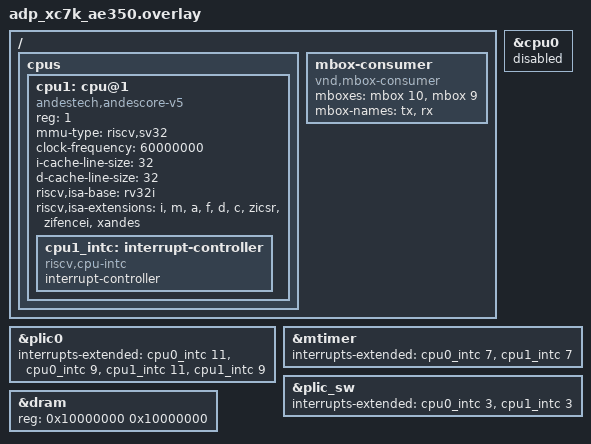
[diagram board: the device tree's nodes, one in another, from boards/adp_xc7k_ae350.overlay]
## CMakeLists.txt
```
#
# Copyright (c) 2021 Carlo Caione <ccaione@baylibre.com>
# Copyright 2023-2026 NXP
# Copyright 2025 Ezurio LLC
#
# SPDX-License-Identifier: Apache-2.0
#

cmake_minimum_required(VERSION 3.28.0)

find_package(Zephyr REQUIRED HINTS $ENV{ZEPHYR_BASE})

if(CONFIG_BOARD_ADP_XC7K_AE350_A25 OR
   CONFIG_BOARD_BL54L15_DVK_NRF54L15_CPUFLPR OR
   CONFIG_BOARD_EK_RA8P1_R7KA8P1KFLCAC_CM33 OR
   CONFIG_BOARD_ESP32C6_DEVKITC_ESP32C6_LPCORE OR
   CONFIG_BOARD_ESP32P4X_FUNCTION_EV_BOARD_ESP32P4_LPCORE OR
   CONFIG_BOARD_ESP32S3_DEVKITC_ESP32S3_APPCPU OR
   CONFIG_BOARD_ESP32_DEVKITC_ESP32_APPCPU OR
   CONFIG_BOARD_FRDM_IMXRT1186_MIMXRT1186_CM7 OR
   CONFIG_BOARD_FRDM_IMXRT700_MIMXRT798S_CM33_CPU1 OR
   CONFIG_BOARD_FRDM_MCXN947_MCXN947_CPU1 OR
   CONFIG_BOARD_IMX943_EVK_MIMX94398_M33 OR
   CONFIG_BOARD_IMX943_EVK_MIMX94398_M7_0 OR
   CONFIG_BOARD_IMX943_EVK_MIMX94398_M7_1 OR
   CONFIG_BOARD_LPCXPRESSO55S69_LPC55S69_CPU1 OR
   CONFIG_BOARD_MCX_N9XX_EVK_MCXN947_CPU1 OR
   CONFIG_BOARD_MIMXRT1160_EVK_MIMXRT1166_CM4 OR
   CONFIG_BOARD_MIMXRT1170_EVK_MIMXRT1176_CM4 OR
   CONFIG_BOARD_MIMXRT1180_EVK_MIMXRT1189_CM7 OR
   CONFIG_BOARD_MIMXRT700_EVK_MIMXRT798S_CM33_CPU1 OR
   CONFIG_BOARD_NRF5340BSIM_NRF5340_CPUNET OR
   CONFIG_BOARD_NRF5340DK_NRF5340_CPUNET OR
   CONFIG_BOARD_NRF54H20DK_NRF54H20_CPUFLPR OR
   CONFIG_BOARD_NRF54H20DK_NRF54H20_CPUPPR OR
   CONFIG_BOARD_NRF54H20DK_NRF54H20_CPURAD OR
   CONFIG_BOARD_NRF54L15DK_NRF54L15_CPUFLPR OR
   CONFIG_BOARD_NRF54LM20DK_NRF54LM20A_CPUFLPR OR
   CONFIG_BOARD_NRF54LM20DK_NRF54LM20B_CPUFLPR OR
   CONFIG_BOARD_NRF54LV10DK_NRF54LV10A_CPUFLPR OR
   CONFIG_BOARD_NRF7120DK_NRF7120_CPUFLPR OR
   CONFIG_BOARD_NRF7120DK_NRF7120E_CPUFLPR OR
   CONFIG_BOARD_NUCLEO_H755ZI_Q_STM32H755XX_M4 OR
   CONFIG_BOARD_STM32H747I_DISCO_STM32H747XX_M4 OR
   CONFIG_SOC_AMD_VERSAL2_RPU OR
   CONFIG_SOC_AMD_VERSALNET_RPU)
  message(STATUS "${BOARD}/${BOARD_QUALIFIERS} compile as remote in this sample")
else()
  message(FATAL_ERROR "${BOARD}/${BOARD_QUALIFIERS} is not supported for this sample")
endif()

project(mbox_ipc_remote)

target_sources(app PRIVATE src/main.c)
```

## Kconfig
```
# Copyright 2024 Nordic Semiconductor ASA
# SPDX-License-Identifier: Apache-2.0

source "Kconfig.zephyr"

config TX_ENABLED
	bool "TX enabled"
	default y
	help
	  Enable TX

config RX_ENABLED
	bool "RX enabled"
	default y
	help
	  Enable RX
```

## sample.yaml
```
sample:
  name: MBOX IPC sample (remote)
tests:
  sample.drivers.mbox_remote:
    platform_allow: nrf5340dk_nrf5340_cpunet adp_xc7k_ae350
    integration_platforms:
      - nrf5340dk_nrf5340_cpunet
    tags: mbox
    harness: remote
```

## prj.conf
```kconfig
CONFIG_STDOUT_CONSOLE=n
CONFIG_MBOX=y
```

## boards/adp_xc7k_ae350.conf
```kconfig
CONFIG_RV_BOOT_HART=1
CONFIG_MP_MAX_NUM_CPUS=1
```

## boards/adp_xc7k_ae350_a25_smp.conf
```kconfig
CONFIG_SMP=n
CONFIG_RV_BOOT_HART=1
CONFIG_MP_MAX_NUM_CPUS=1
```

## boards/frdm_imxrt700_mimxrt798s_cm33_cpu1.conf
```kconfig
# SPDX-FileCopyrightText: Copyright 2026 NXP
# SPDX-License-Identifier: Apache-2.0

CONFIG_BUILD_OUTPUT_HEX=y
CONFIG_SECOND_CORE_MCUX=y
CONFIG_BUILD_OUTPUT_INFO_HEADER=y
CONFIG_GLIKEY_MCUX_GLIKEY=y
```

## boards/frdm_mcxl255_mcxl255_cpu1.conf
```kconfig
CONFIG_SOC_MCXL255_SECOND_CORE=y
CONFIG_BUILD_OUTPUT_HEX=y
```

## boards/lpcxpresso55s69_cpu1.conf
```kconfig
CONFIG_SECOND_CORE_MCUX=y
CONFIG_BUILD_OUTPUT_HEX=y
CONFIG_MBOX_NXP_MAILBOX=y

# For purpose of sample enable UART Console on CPU1
CONFIG_CONSOLE=y
CONFIG_UART_CONSOLE=y
CONFIG_SERIAL=y
CONFIG_UART_INTERRUPT_DRIVEN=y
CONFIG_CLOCK_CONTROL=y
```

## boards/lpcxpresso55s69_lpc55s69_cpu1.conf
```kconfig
CONFIG_SECOND_CORE_MCUX=y
CONFIG_BUILD_OUTPUT_HEX=y

# For purpose of sample enable UART Console on CPU1
CONFIG_CONSOLE=y
CONFIG_UART_CONSOLE=y
CONFIG_SERIAL=y
CONFIG_UART_INTERRUPT_DRIVEN=y
CONFIG_CLOCK_CONTROL=y
```

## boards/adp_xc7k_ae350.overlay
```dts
/*
 * Copyright (c) 2022 Andes Technology Corporation.
 * SPDX-License-Identifier: Apache-2.0
 */

/ {
	cpus {
		cpu1: cpu@1 {
			compatible = "andestech,andescore-v5", "riscv";
			reg = <1>;
			device_type = "cpu";
			mmu-type = "riscv,sv32";
			clock-frequency = <60000000>;
			i-cache-line-size = <32>;
			d-cache-line-size = <32>;
			riscv,isa-base = "rv32i";
			riscv,isa-extensions = "i", "m", "a", "f", "d", "c", "zicsr", "zifencei",
					       "xandes";
			status = "okay";

			cpu1_intc: interrupt-controller {
				compatible = "riscv,cpu-intc";
				#address-cells = <0>;
				#interrupt-cells = <1>;
				interrupt-controller;
			};
		};
	};

	mbox-consumer {
		compatible = "vnd,mbox-consumer";
		mboxes = <&mbox 10>, <&mbox 9>;
		mbox-names = "tx", "rx";
	};
};

&cpu0 {
	status = "disabled";
};

&plic0 {
	interrupts-extended = <&cpu0_intc 11 &cpu0_intc 9
			       &cpu1_intc 11 &cpu1_intc 9>;
};

&mtimer {
	interrupts-extended = <&cpu0_intc 7 &cpu1_intc 7>;
};

&plic_sw {
	interrupts-extended = <&cpu0_intc 3 &cpu1_intc 3>;
};

&dram {
	reg = <0x10000000 0x10000000>;
};
```

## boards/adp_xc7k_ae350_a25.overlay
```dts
/*
 * Copyright (c) 2022 Andes Technology Corporation.
 * SPDX-License-Identifier: Apache-2.0
 */

/ {
	cpus {
		cpu1: cpu@1 {
			compatible = "andestech,a25", "andestech,andescore-v5", "riscv";
			reg = <1>;
			device_type = "cpu";
			mmu-type = "riscv,sv32";
			clock-frequency = <60000000>;
			i-cache-line-size = <32>;
			d-cache-line-size = <32>;
			riscv,isa-base = "rv32i";
			riscv,isa-extensions = "i", "m", "a", "f", "d", "c", "zicsr", "zifencei",
					       "zba", "zbb", "zbc", "zbs", "xandes";
			status = "okay";

			cpu1_intc: interrupt-controller {
				compatible = "riscv,cpu-intc";
				#address-cells = <0>;
				#interrupt-cells = <1>;
				interrupt-controller;
			};
		};
	};

	mbox-consumer {
		compatible = "vnd,mbox-consumer";
		mboxes = <&mbox 10>, <&mbox 9>;
		mbox-names = "tx", "rx";
	};
};

&cpu0 {
	status = "disabled";
};

&plic0 {
	interrupts-extended = <&cpu0_intc 11 &cpu0_intc 9
			       &cpu1_intc 11 &cpu1_intc 9>;
};

&mtimer {
	interrupts-extended = <&cpu0_intc 7 &cpu1_intc 7>;
};

&plic_sw {
	interrupts-extended = <&cpu0_intc 3 &cpu1_intc 3>;
};

&dram {
	reg = <0x10000000 0x10000000>;
};
```

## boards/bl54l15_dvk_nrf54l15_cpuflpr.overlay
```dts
/*
 * Copyright 2024 Nordic Semiconductor ASA
 * Copyright 2025 Ezurio LLC
 * SPDX-License-Identifier: Apache-2.0
 */

/ {
	mbox-consumer {
		compatible = "vnd,mbox-consumer";
		mboxes = <&cpuflpr_vevif_rx 21>, <&cpuflpr_vevif_tx 20>;
		mbox-names = "rx", "tx";
	};
};

&cpuflpr_vevif_rx {
	status = "okay";
};

&cpuflpr_vevif_tx {
	status = "okay";
};

&uart30 {
	/delete-property/ hw-flow-control;
};
```

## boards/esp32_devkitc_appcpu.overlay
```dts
/*
 * Copyright (c) 2024 Felipe Neves.
 *
 * SPDX-License-Identifier: Apache-2.0
 */

/ {
	chosen {
		zephyr,sram = &sram1;
		zephyr,ipc_shm = &shm0;
		zephyr,ipc = &mbox0;
	};

	mbox-consumer {
		compatible = "vnd,mbox-consumer";
		mboxes = <&mbox0 0>, <&mbox0 1>;
		mbox-names = "tx", "rx";
	};
};

&mbox0 {
	status = "okay";
};
```

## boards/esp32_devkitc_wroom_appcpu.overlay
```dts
/*
 * Copyright (c) 2024 Felipe Neves.
 *
 * SPDX-License-Identifier: Apache-2.0
 */

/ {
	chosen {
		zephyr,sram = &sram0;
		zephyr,ipc_shm = &shm0;
		zephyr,ipc = &mbox0;
	};

	mbox-consumer {
		compatible = "vnd,mbox-consumer";
		mboxes = <&mbox0 0>, <&mbox0 1>;
		mbox-names = "tx", "rx";
	};
};

&mbox0 {
	status = "okay";
};
```

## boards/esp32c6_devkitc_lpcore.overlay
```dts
/*
 * Copyright (c) 2024 Felipe Neves.
 *
 * SPDX-License-Identifier: Apache-2.0
 */

/ {
	chosen {
		zephyr,ipc_shm = &ipc_shm;
		zephyr,ipc = &mbox0;
	};

	mbox-consumer {
		compatible = "vnd,mbox-consumer";
		mboxes = <&mbox0 1>, <&mbox0 0>;
		mbox-names = "tx", "rx";
	};
};

&lp_uart {
	status = "okay";
};
```

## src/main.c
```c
/*
 * Copyright (c) 2021 Carlo Caione <ccaione@baylibre.com>
 *
 * SPDX-License-Identifier: Apache-2.0
 */

#include <string.h>

#include <zephyr/kernel.h>
#include <zephyr/drivers/mbox.h>
#include <zephyr/sys/printk.h>
#include <zephyr/sys/util.h>

/*
 * Largest payload this sample is able to build. Drivers advertising an MTU
 * bigger than this are driven in signalling mode instead.
 */
#define MAX_MSG_SIZE 64

#if !defined(CONFIG_RX_ENABLED) && !defined(CONFIG_TX_ENABLED)
#error "At least one of CONFIG_RX_ENABLED or CONFIG_TX_ENABLED must be set"
#endif

#ifdef CONFIG_RX_ENABLED
static void callback(const struct device *dev, mbox_channel_id_t channel_id,
		     void *user_data, struct mbox_msg *data)
{
	if ((data != NULL) && (data->data != NULL) && (data->size > 0U)) {
		uint32_t counter = 0;

		memcpy(&counter, data->data, MIN(sizeof(counter), data->size));

		printk("Pong (on channel %d) counter %u in %u byte(s)\n", channel_id,
		       counter, (unsigned int)data->size);
	} else {
		printk("Pong (on channel %d)\n", channel_id);
	}
}
#endif /* CONFIG_RX_ENABLED */

#ifdef CONFIG_TX_ENABLED
static uint8_t tx_data[MAX_MSG_SIZE];
#endif /* CONFIG_TX_ENABLED */

int main(void)
{
	int ret;

	printk("Hello from REMOTE - %s\n", CONFIG_BOARD_TARGET);

#ifdef CONFIG_RX_ENABLED
	const struct mbox_dt_spec rx_channel = MBOX_DT_SPEC_GET(DT_PATH(mbox_consumer), rx);

	printk("Maximum RX channels: %d\n", mbox_max_channels_get_dt(&rx_channel));

	ret = mbox_register_callback_dt(&rx_channel, callback, NULL);
	if (ret < 0) {
		printk("Could not register callback (%d)\n", ret);
		return 0;
	}

	ret = mbox_set_enabled_dt(&rx_channel, true);
	if (ret < 0) {
		printk("Could not enable RX channel %d (%d)\n", rx_channel.channel_id, ret);
		return 0;
	}
#endif /* CONFIG_RX_ENABLED */

#ifdef CONFIG_TX_ENABLED
	const struct mbox_dt_spec tx_channel = MBOX_DT_SPEC_GET(DT_PATH(mbox_consumer), tx);
	struct mbox_msg msg;
	struct mbox_msg *msg_ptr = NULL;
	uint32_t counter = 0;
	int mtu;

	mtu = mbox_mtu_get_dt(&tx_channel);

	printk("Maximum bytes of data in the TX message: %d\n", mtu);
	printk("Maximum TX channels: %d\n", mbox_max_channels_get_dt(&tx_channel));

	/*
	 * A non-zero MTU means the driver operates in data transfer mode, where
	 * mbox_send() must be given a message whose size matches the MTU. A zero
	 * (or unsupported) MTU means signalling mode, where the message must be
	 * NULL.
	 */
	if (mtu > (int)sizeof(tx_data)) {
		printk("MTU exceeds %u bytes, using signalling mode instead\n",
		       (unsigned int)sizeof(tx_data));
	} else if (mtu > 0) {
		msg.data = tx_data;
		msg.size = (size_t)mtu;
		msg_ptr = &msg;
	}

	while (1) {
#if defined(CONFIG_MULTITHREADING)
		k_sleep(K_MSEC(3000));
#else
		k_busy_wait(3000000);
#endif

		if (msg_ptr != NULL) {
			counter++;
			memset(tx_data, 0, msg.size);
			memcpy(tx_data, &counter, MIN(sizeof(counter), msg.size));
		}

		printk("Ping (on channel %d)\n", tx_channel.channel_id);

		ret = mbox_send_dt(&tx_channel, msg_ptr);
		if (ret < 0) {
			printk("Could not send (%d)\n", ret);
			return 0;
		}
	}
#endif /* CONFIG_TX_ENABLED */
	return 0;
}
```
